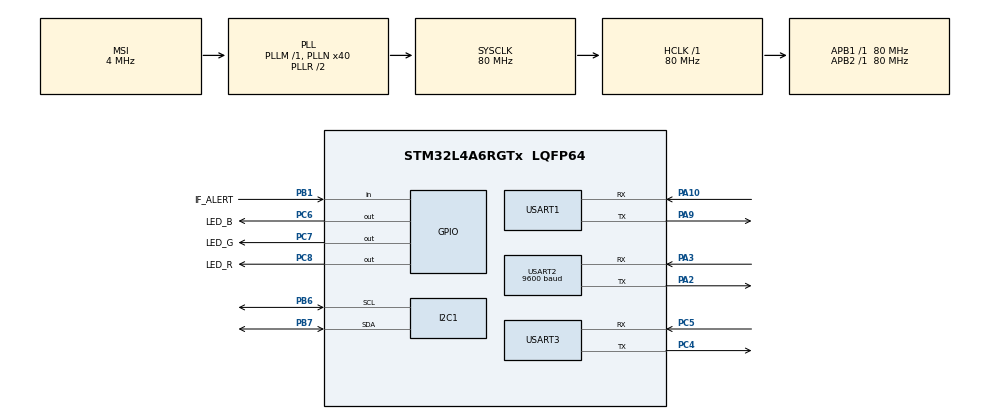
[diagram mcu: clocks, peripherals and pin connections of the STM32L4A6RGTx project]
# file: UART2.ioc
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FREERTOS.Tasks01=defaultTask,0,128,StartDefaultTask,Default,NULL
Mcu.Family=STM32L4
Mcu.Name=STM32L4A6RGTx
Mcu.Package=LQFP64
NVIC.I2C1_ER_IRQn=true\:5\:0\:false\:false\:true\:true\:true\:true
NVIC.I2C1_EV_IRQn=true\:5\:0\:false\:false\:true\:true\:true\:true
NVIC.PriorityGroup=NVIC_PRIORITYGROUP_4
NVIC.TIM6_DAC_IRQn=true\:0\:0\:false\:false\:true\:false\:false\:true
NVIC.TimeBase=TIM6_DAC_IRQn
NVIC.TimeBaseIP=TIM6
NVIC.USART2_IRQn=true\:5\:0\:false\:false\:true\:true\:true\:true
PA10.Mode=Asynchronous
PA10.Signal=USART1_RX
PA13\ (JTMS/SWDIO).Mode=Serial_Wire
PA13\ (JTMS/SWDIO).Signal=SYS_JTMS-SWDIO
PA14\ (JTCK/SWCLK).Mode=Serial_Wire
PA14\ (JTCK/SWCLK).Signal=SYS_JTCK-SWCLK
PA2.Mode=Asynchronous
PA2.Signal=USART2_TX
PA3.Mode=Asynchronous
PA3.Signal=USART2_RX
PA9.Mode=Asynchronous
PA9.Signal=USART1_TX
PB1.GPIO_Label=IF_ALERT
PB1.GPIO_PuPd=GPIO_PULLUP
PB1.Signal=GPIO_Input
PB6.Mode=I2C
PB6.Signal=I2C1_SCL
PB7.Mode=I2C
PB7.Signal=I2C1_SDA
PC4.Mode=Asynchronous
PC4.Signal=USART3_TX
PC5.Mode=Asynchronous
PC5.Signal=USART3_RX
PC6.GPIO_Label=LED_B
PC6.PinState=GPIO_PIN_SET
PC6.Signal=GPIO_Output
PC7.GPIO_Label=LED_G
PC7.PinState=GPIO_PIN_SET
PC7.Signal=GPIO_Output
PC8.GPIO_Label=LED_R
PC8.PinState=GPIO_PIN_SET
PC8.Signal=GPIO_Output
PH0-OSC_IN\ (PH0).Mode=HSE-External-Oscillator
PH0-OSC_IN\ (PH0).Signal=RCC_OSC_IN
PH1-OSC_OUT\ (PH1).Mode=HSE-External-Oscillator
PH1-OSC_OUT\ (PH1).Signal=RCC_OSC_OUT
ProjectManager.HeapSize=0x200
ProjectManager.StackSize=0x400
ProjectManager.TargetToolchain=TrueSTUDIO
RCC.ADCFreq_Value=32000000
RCC.AHBFreq_Value=80000000
RCC.APB1Freq_Value=80000000
RCC.APB1TimFreq_Value=80000000
RCC.APB2Freq_Value=80000000
RCC.APB2TimFreq_Value=80000000
RCC.CortexFreq_Value=80000000
RCC.HCLKFreq_Value=80000000
RCC.HSE_VALUE=20000000
RCC.HSI48_VALUE=48000000
RCC.HSI_VALUE=16000000
RCC.LSE_VALUE=32768
RCC.MSI_VALUE=4000000
RCC.PLLN=40
RCC.PLLSAI1N=16
RCC.SYSCLKFreq_VALUE=80000000
RCC.SYSCLKSource=RCC_SYSCLKSOURCE_PLLCLK
RCC.USBFreq_Value=32000000
RCC.VCOOutputFreq_Value=160000000
USART1.VirtualMode-Asynchronous=VM_ASYNC
USART2.BaudRate=9600
USART2.VirtualMode-Asynchronous=VM_ASYNC
USART3.VirtualMode-Asynchronous=VM_ASYNC
VP_FREERTOS_VS_CMSIS_V1.Mode=CMSIS_V1
VP_SYS_VS_tim6.Mode=TIM6
board=custom

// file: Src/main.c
/* USER CODE BEGIN Header */
/**
  ******************************************************************************
  * @file           : main.c
  * @brief          : Main program body
  ******************************************************************************
  * @attention
  *
  * <h2><center>&copy; Copyright (c) 2019 STMicroelectronics.
  * All rights reserved.</center></h2>
  *
  * This software component is licensed by ST under Ultimate Liberty license
  * SLA0044, the "License"; You may not use this file except in compliance with
  * the License. You may obtain a copy of the License at:
  *                             www.st.com/SLA0044
  *
  ******************************************************************************
  */
/* USER CODE END Header */

#include "main.h"
#include "cmsis_os.h"

I2C_HandleTypeDef hi2c1;

UART_HandleTypeDef huart1;
UART_HandleTypeDef huart2;
UART_HandleTypeDef huart3;

osThreadId defaultTaskHandle;
/* USER CODE BEGIN PV */
osThreadId uartReadTaskHandle;
/* USER CODE END PV */

void SystemClock_Config(void);
static void MX_GPIO_Init(void);
static void MX_USART2_UART_Init(void);
static void MX_I2C1_Init(void);
static void MX_USART1_UART_Init(void);
static void MX_USART3_UART_Init(void);
void StartDefaultTask(void const * argument);

/* USER CODE BEGIN PFP */
void StartUartReadTask(void const *argument);

/* USER CODE END PFP */

int main(void)
{

  /* MCU Configuration--------------------------------------------------------*/

  /* Reset of all peripherals, Initializes the Flash interface and the Systick. */
  HAL_Init();

  /* Configure the system clock */
  SystemClock_Config();

  /* Initialize all configured peripherals */
  MX_GPIO_Init();
  MX_USART2_UART_Init();
  MX_I2C1_Init();
  MX_USART1_UART_Init();
  MX_USART3_UART_Init();

  /* Create the thread(s) */
  /* definition and creation of defaultTask */
  osThreadDef(defaultTask, StartDefaultTask, osPriorityNormal, 0, 128);
  defaultTaskHandle = osThreadCreate(osThread(defaultTask), NULL);

  /* USER CODE BEGIN RTOS_THREADS */
  /* add threads, ... */
  osThreadDef(uartReadTask, StartUartReadTask, osPriorityNormal, 0, 128);
  uartReadTaskHandle = osThreadCreate(osThread(uartReadTask), NULL);
  /* USER CODE END RTOS_THREADS */

  /* Start scheduler */
  osKernelStart();

  /* We should never get here as control is now taken by the scheduler */

  /* Infinite loop */
  while (1)
  {

  }
}

void SystemClock_Config(void)
{
  RCC_OscInitTypeDef RCC_OscInitStruct = {0};
  RCC_ClkInitTypeDef RCC_ClkInitStruct = {0};
  RCC_PeriphCLKInitTypeDef PeriphClkInit = {0};

  /** Initializes the CPU, AHB and APB busses clocks
  */
  RCC_OscInitStruct.OscillatorType = RCC_OSCILLATORTYPE_MSI;
  RCC_OscInitStruct.MSIState = RCC_MSI_ON;
  RCC_OscInitStruct.MSICalibrationValue = 0;
  RCC_OscInitStruct.MSIClockRange = RCC_MSIRANGE_6;
  RCC_OscInitStruct.PLL.PLLState = RCC_PLL_ON;
  RCC_OscInitStruct.PLL.PLLSource = RCC_PLLSOURCE_MSI;
  RCC_OscInitStruct.PLL.PLLM = 1;
  RCC_OscInitStruct.PLL.PLLN = 40;
  RCC_OscInitStruct.PLL.PLLP = RCC_PLLP_DIV2;
  RCC_OscInitStruct.PLL.PLLQ = RCC_PLLQ_DIV2;
  RCC_OscInitStruct.PLL.PLLR = RCC_PLLR_DIV2;
  if (HAL_RCC_OscConfig(&RCC_OscInitStruct) != HAL_OK)
  {
    Error_Handler();
  }
  /** Initializes the CPU, AHB and APB busses clocks
  */
  RCC_ClkInitStruct.ClockType = RCC_CLOCKTYPE_HCLK|RCC_CLOCKTYPE_SYSCLK
                              |RCC_CLOCKTYPE_PCLK1|RCC_CLOCKTYPE_PCLK2;
  RCC_ClkInitStruct.SYSCLKSource = RCC_SYSCLKSOURCE_PLLCLK;
  RCC_ClkInitStruct.AHBCLKDivider = RCC_SYSCLK_DIV1;
  RCC_ClkInitStruct.APB1CLKDivider = RCC_HCLK_DIV1;
  RCC_ClkInitStruct.APB2CLKDivider = RCC_HCLK_DIV1;

  if (HAL_RCC_ClockConfig(&RCC_ClkInitStruct, FLASH_LATENCY_4) != HAL_OK)
  {
    Error_Handler();
  }
  PeriphClkInit.PeriphClockSelection = RCC_PERIPHCLK_USART1|RCC_PERIPHCLK_USART2
                              |RCC_PERIPHCLK_USART3|RCC_PERIPHCLK_I2C1;
  PeriphClkInit.Usart1ClockSelection = RCC_USART1CLKSOURCE_PCLK2;
  PeriphClkInit.Usart2ClockSelection = RCC_USART2CLKSOURCE_PCLK1;
  PeriphClkInit.Usart3ClockSelection = RCC_USART3CLKSOURCE_PCLK1;
  PeriphClkInit.I2c1ClockSelection = RCC_I2C1CLKSOURCE_PCLK1;
  if (HAL_RCCEx_PeriphCLKConfig(&PeriphClkInit) != HAL_OK)
  {
    Error_Handler();
  }
  /** Configure the main internal regulator output voltage
  */
  if (HAL_PWREx_ControlVoltageScaling(PWR_REGULATOR_VOLTAGE_SCALE1) != HAL_OK)
  {
    Error_Handler();
  }
}

static void MX_I2C1_Init(void)
{

  hi2c1.Instance = I2C1;
  hi2c1.Init.Timing = 0x10909CEC;
  hi2c1.Init.OwnAddress1 = 0;
  hi2c1.Init.AddressingMode = I2C_ADDRESSINGMODE_7BIT;
  hi2c1.Init.DualAddressMode = I2C_DUALADDRESS_DISABLE;
  hi2c1.Init.OwnAddress2 = 0;
  hi2c1.Init.OwnAddress2Masks = I2C_OA2_NOMASK;
  hi2c1.Init.GeneralCallMode = I2C_GENERALCALL_DISABLE;
  hi2c1.Init.NoStretchMode = I2C_NOSTRETCH_DISABLE;
  if (HAL_I2C_Init(&hi2c1) != HAL_OK)
  {
    Error_Handler();
  }
  /** Configure Analogue filter
  */
  if (HAL_I2CEx_ConfigAnalogFilter(&hi2c1, I2C_ANALOGFILTER_ENABLE) != HAL_OK)
  {
    Error_Handler();
  }
  /** Configure Digital filter
  */
  if (HAL_I2CEx_ConfigDigitalFilter(&hi2c1, 0) != HAL_OK)
  {
    Error_Handler();
  }

}

static void MX_USART1_UART_Init(void)
{

  huart1.Instance = USART1;
  huart1.Init.BaudRate = 115200;
  huart1.Init.WordLength = UART_WORDLENGTH_8B;
  huart1.Init.StopBits = UART_STOPBITS_1;
  huart1.Init.Parity = UART_PARITY_NONE;
  huart1.Init.Mode = UART_MODE_TX_RX;
  huart1.Init.HwFlowCtl = UART_HWCONTROL_NONE;
  huart1.Init.OverSampling = UART_OVERSAMPLING_16;
  huart1.Init.OneBitSampling = UART_ONE_BIT_SAMPLE_DISABLE;
  huart1.AdvancedInit.AdvFeatureInit = UART_ADVFEATURE_NO_INIT;
  if (HAL_UART_Init(&huart1) != HAL_OK)
  {
    Error_Handler();
  }

}

static void MX_USART2_UART_Init(void)
{

  huart2.Instance = USART2;
  huart2.Init.BaudRate = 9600;
  huart2.Init.WordLength = UART_WORDLENGTH_8B;
  huart2.Init.StopBits = UART_STOPBITS_1;
  huart2.Init.Parity = UART_PARITY_NONE;
  huart2.Init.Mode = UART_MODE_TX_RX;
  huart2.Init.HwFlowCtl = UART_HWCONTROL_NONE;
  huart2.Init.OverSampling = UART_OVERSAMPLING_16;
  huart2.Init.OneBitSampling = UART_ONE_BIT_SAMPLE_DISABLE;
  huart2.AdvancedInit.AdvFeatureInit = UART_ADVFEATURE_NO_INIT;
  if (HAL_UART_Init(&huart2) != HAL_OK)
  {
    Error_Handler();
  }

}

static void MX_USART3_UART_Init(void)
{

  huart3.Instance = USART3;
  huart3.Init.BaudRate = 115200;
  huart3.Init.WordLength = UART_WORDLENGTH_8B;
  huart3.Init.StopBits = UART_STOPBITS_1;
  huart3.Init.Parity = UART_PARITY_NONE;
  huart3.Init.Mode = UART_MODE_TX_RX;
  huart3.Init.HwFlowCtl = UART_HWCONTROL_NONE;
  huart3.Init.OverSampling = UART_OVERSAMPLING_16;
  huart3.Init.OneBitSampling = UART_ONE_BIT_SAMPLE_DISABLE;
  huart3.AdvancedInit.AdvFeatureInit = UART_ADVFEATURE_NO_INIT;
  if (HAL_UART_Init(&huart3) != HAL_OK)
  {
    Error_Handler();
  }

}

static void MX_GPIO_Init(void)
{
  GPIO_InitTypeDef GPIO_InitStruct = {0};

  /* GPIO Ports Clock Enable */
  __HAL_RCC_GPIOH_CLK_ENABLE();
  __HAL_RCC_GPIOA_CLK_ENABLE();
  __HAL_RCC_GPIOC_CLK_ENABLE();
  __HAL_RCC_GPIOB_CLK_ENABLE();

  /*Configure GPIO pin Output Level */
  HAL_GPIO_WritePin(GPIOC, LED_B_Pin|LED_G_Pin|LED_R_Pin, GPIO_PIN_SET);

  /*Configure GPIO pin : IF_ALERT_Pin */
  GPIO_InitStruct.Pin = IF_ALERT_Pin;
  GPIO_InitStruct.Mode = GPIO_MODE_INPUT;
  GPIO_InitStruct.Pull = GPIO_PULLUP;
  HAL_GPIO_Init(IF_ALERT_GPIO_Port, &GPIO_InitStruct);

  /*Configure GPIO pins : LED_B_Pin LED_G_Pin LED_R_Pin */
  GPIO_InitStruct.Pin = LED_B_Pin|LED_G_Pin|LED_R_Pin;
  GPIO_InitStruct.Mode = GPIO_MODE_OUTPUT_PP;
  GPIO_InitStruct.Pull = GPIO_NOPULL;
  GPIO_InitStruct.Speed = GPIO_SPEED_FREQ_LOW;
  HAL_GPIO_Init(GPIOC, &GPIO_InitStruct);

}

/* USER CODE BEGIN 4 */
void StartUartReadTask(void const *argument)
{
    // HAL_ADC_Start_IT(&hadc1);
    //HAL_UART_Receive_IT(&huart3, input, 6);

    // char s[10] = "Alive\r\n";
    // HAL_ADC_Start(&hadc2);
    for (;;)
    {
        // HAL_UART_Transmit_IT(&huart2, s, strlen(s));
        // HAL_GPIO_TogglePin(GPIOC, LED_G_Pin);
        // HAL_ADC_PollForConversion(&hadc2, 1000);
        // int a = HAL_ADC_GetValue(&hadc2);
        // char msg[50];
        // sprintf(msg, "ADC Value %d\r\n", a);
        // HAL_UART_Transmit(&huart2, buffer, strlen(buffer), 100);
        // if (HAL_ADC_STATE_READY & HAL_ADC_GetState(&hadc2)) HAL_ADC_Start_IT(&hadc2);
        HAL_UART_Transmit(&huart2, "Start ADC read\r\n", strlen("Start ADC read\r\n"), 100);
        osDelay(100);
    }
}
/* USER CODE END 4 */

void StartDefaultTask(void const * argument)
{

  for(;;)
  {
    osDelay(1);
  }
}

void HAL_TIM_PeriodElapsedCallback(TIM_HandleTypeDef *htim)
{
  if (htim->Instance == TIM6) {
    HAL_IncTick();
  }
}

void Error_Handler(void)
{
}

/************************ (C) COPYRIGHT STMicroelectronics *****END OF FILE****/
